# ExampleDevice register map
Vendor: Example & Co; File version: 1.0
Example device for parser tests.
Registers are access not given, no defined reset value unless marked. A register's access mark holds for its fields unless they carry their own. Offsets are from the block's base; lines under a group give offsets from that group; [hi:lo] are bit positions; {n}, {i} and the like mark numbered series; 'fields as' and 'values as' point back to an identical list; <NAME> marks a mode.

## Memory map
0x40000000 BASE
0x50000000 DERIVED
0x60000000 CLUSTERED

## BASE
Base 0x40000000
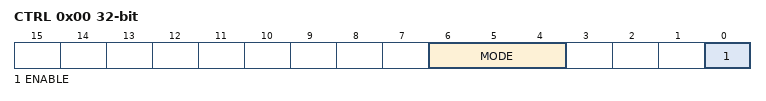
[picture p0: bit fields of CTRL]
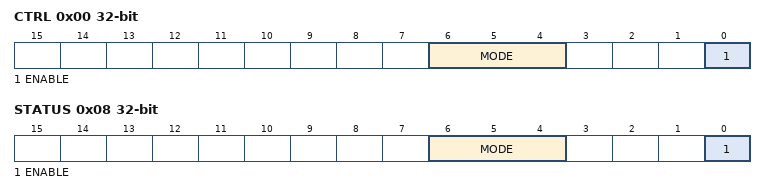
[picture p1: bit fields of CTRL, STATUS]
0x00 CTRL
  [6:4] MODE
  [0] ENABLE
    0=Disabled; 1=Enabled
{0x10+4i} DATA{i} (i=0..1) ro

## DERIVED
Base 0x50000000
0x00 CTRL
  [6:4] MODE
  [0] ENABLE
    0=Disabled; 1=Enabled
0x08 STATUS
  [6:4] MODE
  [0] ENABLE
    0=Disabled; 1=Enabled
{0x10+4i} DATA{i} (i=0..1) ro

## CLUSTERED
Base 0x60000000
0x00 CH{x} (x=A,B; step 0x20) group
  0x04 VALUE 16-bit
0x40 CLBASE group
  0x04 VALUE2 16-bit
0x60 CLDERIVED group
  0x04 VALUE2 16-bit
